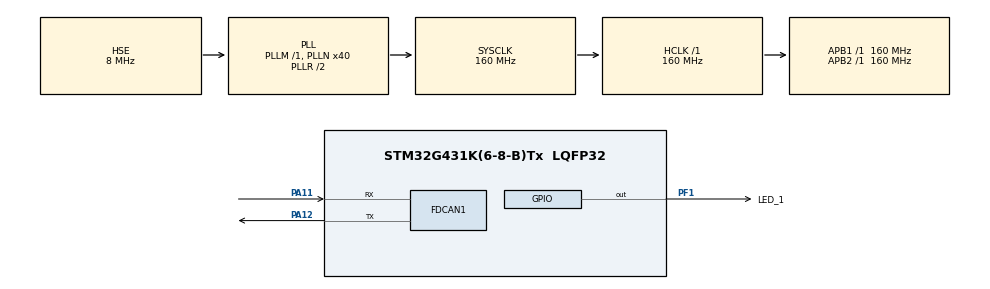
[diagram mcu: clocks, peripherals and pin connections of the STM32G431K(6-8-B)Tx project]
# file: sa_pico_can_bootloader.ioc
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FDCAN1.DataPrescaler=20
FDCAN1.DataSyncJumpWidth=3
FDCAN1.DataTimeSeg1=11
FDCAN1.DataTimeSeg2=14
FDCAN1.NominalPrescaler=20
FDCAN1.NominalSyncJumpWidth=3
FDCAN1.NominalTimeSeg1=11
FDCAN1.NominalTimeSeg2=4
Mcu.Family=STM32G4
Mcu.Name=STM32G431K(6-8-B)Tx
Mcu.Package=LQFP32
NVIC.FDCAN1_IT0_IRQn=true\:0\:0\:false\:false\:true\:true\:true
NVIC.PriorityGroup=NVIC_PRIORITYGROUP_4
NVIC.TIM1_UP_TIM16_IRQn=true\:0\:0\:false\:false\:true\:true\:true
NVIC.TIM3_IRQn=true\:0\:0\:false\:false\:true\:true\:true
PA0.Signal=ADC1_IN1
PA1.Signal=ADC1_IN2
PA11.Mode=FDCAN_Activate
PA11.Signal=FDCAN1_RX
PA12.Mode=FDCAN_Activate
PA12.Signal=FDCAN1_TX
PA13.Mode=Serial_Wire
PA13.Signal=SYS_JTMS-SWDIO
PA14.Mode=Serial_Wire
PA14.Signal=SYS_JTCK-SWCLK
PA2.Signal=LPUART1_TX
PA3.Signal=LPUART1_RX
PA4.Signal=COMP_DAC11_group
PA5.Signal=COMP_DAC12_group
PA8.Signal=I2C2_SDA
PA9.Signal=I2C2_SCL
PB3.Signal=SPI1_SCK
PB4.Signal=SPI3_MISO
PB5.Signal=SPI1_MOSI
PB7.Signal=I2C1_SDA
PB8-BOOT0.Signal=I2C1_SCL
PF0-OSC_IN.Mode=HSE-External-Clock-Source
PF0-OSC_IN.Signal=RCC_OSC_IN
PF1-OSC_OUT.GPIO_Label=LED_1
PF1-OSC_OUT.Signal=GPIO_Output
ProjectManager.HeapSize=0x2000
ProjectManager.StackSize=0x4000
ProjectManager.TargetToolchain=Makefile
RCC.ADC12Freq_Value=160000000
RCC.AHBFreq_Value=160000000
RCC.APB1Freq_Value=160000000
RCC.APB1TimFreq_Value=160000000
RCC.APB2Freq_Value=160000000
RCC.APB2TimFreq_Value=160000000
RCC.CortexFreq_Value=160000000
RCC.EXTERNAL_CLOCK_VALUE=12288000
RCC.HCLKFreq_Value=160000000
RCC.HSE_VALUE=8000000
RCC.HSI48_VALUE=48000000
RCC.HSI_VALUE=16000000
RCC.LSE_VALUE=32768
RCC.PLLN=40
RCC.PLLSourceVirtual=RCC_PLLSOURCE_HSE
RCC.SYSCLKFreq_VALUE=160000000
RCC.SYSCLKSource=RCC_SYSCLKSOURCE_PLLCLK
RCC.USBFreq_Value=160000000
RCC.VCOOutputFreq_Value=320000000
SH.COMP_DAC11_group.0=DAC1_OUT1
SH.COMP_DAC12_group.0=DAC1_OUT2
TIM1.AutoReloadPreload=TIM_AUTORELOAD_PRELOAD_DISABLE
TIM1.PeriodNoDither=10000-1
TIM1.Prescaler=16000-1
TIM3.AutoReloadPreload=TIM_AUTORELOAD_PRELOAD_DISABLE
TIM3.PeriodNoDither=60000-1
TIM3.Prescaler=1600-1
TIM6.PeriodNoDither=10-1
TIM6.Prescaler=16000-1
VP_SYS_VS_DBSignals.Mode=DisableDeadBatterySignals
VP_TIM1_VS_ClockSourceINT.Mode=Internal
VP_TIM3_VS_ClockSourceINT.Mode=Internal
VP_TIM6_VS_ClockSourceINT.Mode=Enable_Timer
board=custom

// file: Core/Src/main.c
/* USER CODE BEGIN Header */
/**
  ******************************************************************************
  * @file           : main.c
  * @brief          : Main program body
  ******************************************************************************
  * @attention
  *
  * <h2><center>&copy; Copyright (c) 2022 STMicroelectronics.
  * All rights reserved.</center></h2>
  *
  * This software component is licensed by ST under BSD 3-Clause license,
  * the "License"; You may not use this file except in compliance with the
  * License. You may obtain a copy of the License at:
  *                        opensource.org/licenses/BSD-3-Clause
  *
  ******************************************************************************
  */
/* USER CODE END Header */
#include "main.h"
#include "fdcan.h"
#include "tim.h"
#include "gpio.h"

void SystemClock_Config(void);
/* USER CODE BEGIN PFP */
extern void while1_in_mainCpp();
extern void AppInit();
/* USER CODE END PFP */

int main(void)
{

  /* MCU Configuration--------------------------------------------------------*/

  /* Reset of all peripherals, Initializes the Flash interface and the Systick. */
  HAL_Init();

  /* Configure the system clock */
  SystemClock_Config();

  /* Initialize all configured peripherals */
  MX_GPIO_Init();
  MX_FDCAN1_Init();
  MX_TIM1_Init();
  MX_TIM3_Init();
  MX_TIM6_Init();
  /* USER CODE BEGIN 2 */
  AppInit();
  /* USER CODE END 2 */

  /* Infinite loop */
  /* USER CODE BEGIN WHILE */
  while (1)
  {
      while1_in_mainCpp();
    /* USER CODE END WHILE */

  }
}

void SystemClock_Config(void)
{
  RCC_OscInitTypeDef RCC_OscInitStruct = {0};
  RCC_ClkInitTypeDef RCC_ClkInitStruct = {0};
  RCC_PeriphCLKInitTypeDef PeriphClkInit = {0};

  /** Configure the main internal regulator output voltage
  */
  HAL_PWREx_ControlVoltageScaling(PWR_REGULATOR_VOLTAGE_SCALE1_BOOST);
  /** Initializes the RCC Oscillators according to the specified parameters
  * in the RCC_OscInitTypeDef structure.
  */
  RCC_OscInitStruct.OscillatorType = RCC_OSCILLATORTYPE_HSE;
  RCC_OscInitStruct.HSEState = RCC_HSE_BYPASS;
  RCC_OscInitStruct.PLL.PLLState = RCC_PLL_ON;
  RCC_OscInitStruct.PLL.PLLSource = RCC_PLLSOURCE_HSE;
  RCC_OscInitStruct.PLL.PLLM = RCC_PLLM_DIV1;
  RCC_OscInitStruct.PLL.PLLN = 40;
  RCC_OscInitStruct.PLL.PLLP = RCC_PLLP_DIV2;
  RCC_OscInitStruct.PLL.PLLQ = RCC_PLLQ_DIV2;
  RCC_OscInitStruct.PLL.PLLR = RCC_PLLR_DIV2;
  if (HAL_RCC_OscConfig(&RCC_OscInitStruct) != HAL_OK)
  {
    Error_Handler();
  }
  /** Initializes the CPU, AHB and APB buses clocks
  */
  RCC_ClkInitStruct.ClockType = RCC_CLOCKTYPE_HCLK|RCC_CLOCKTYPE_SYSCLK
                              |RCC_CLOCKTYPE_PCLK1|RCC_CLOCKTYPE_PCLK2;
  RCC_ClkInitStruct.SYSCLKSource = RCC_SYSCLKSOURCE_PLLCLK;
  RCC_ClkInitStruct.AHBCLKDivider = RCC_SYSCLK_DIV1;
  RCC_ClkInitStruct.APB1CLKDivider = RCC_HCLK_DIV1;
  RCC_ClkInitStruct.APB2CLKDivider = RCC_HCLK_DIV1;

  if (HAL_RCC_ClockConfig(&RCC_ClkInitStruct, FLASH_LATENCY_4) != HAL_OK)
  {
    Error_Handler();
  }
  /** Initializes the peripherals clocks
  */
  PeriphClkInit.PeriphClockSelection = RCC_PERIPHCLK_FDCAN;
  PeriphClkInit.FdcanClockSelection = RCC_FDCANCLKSOURCE_PCLK1;
  if (HAL_RCCEx_PeriphCLKConfig(&PeriphClkInit) != HAL_OK)
  {
    Error_Handler();
  }
}

void Error_Handler(void)
{
  __disable_irq();
  while (1)
  {
  }
}

/************************ (C) COPYRIGHT STMicroelectronics *****END OF FILE****/
